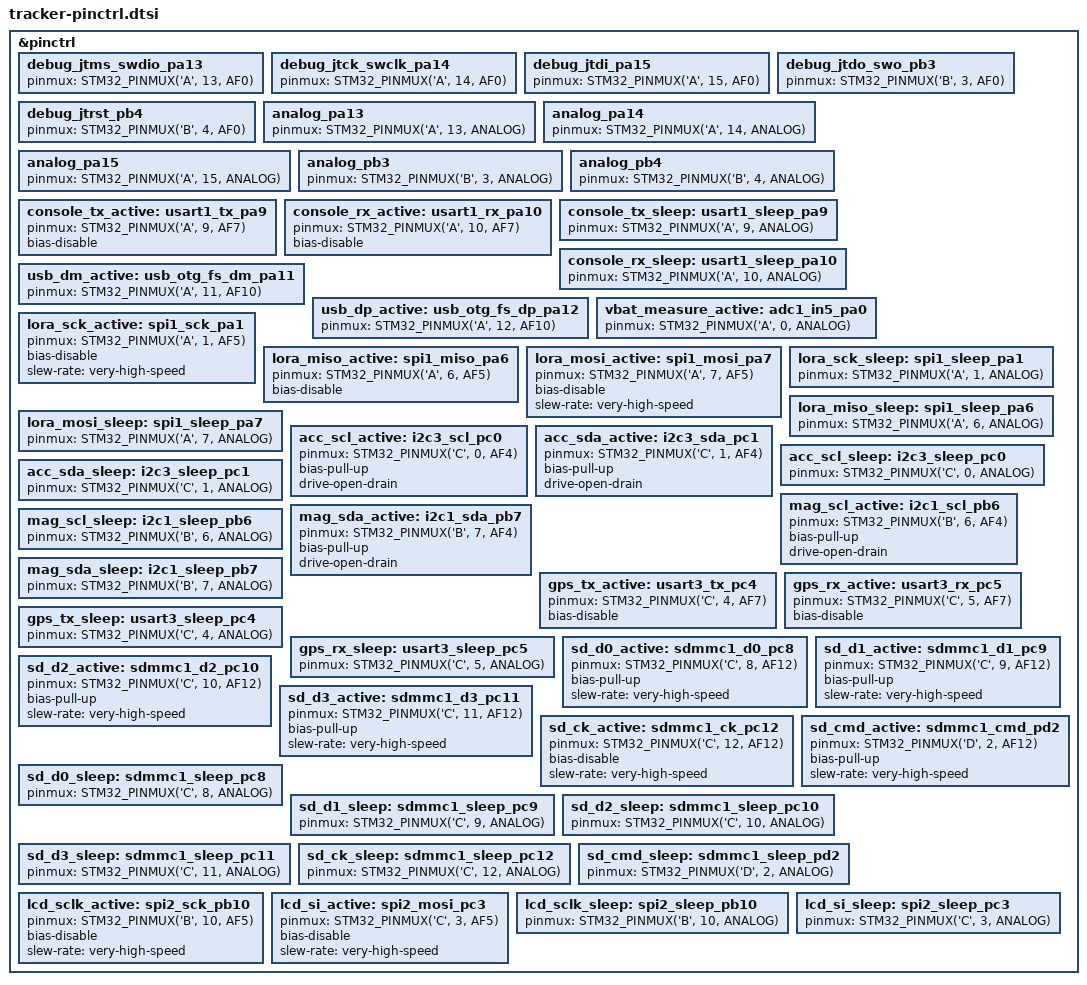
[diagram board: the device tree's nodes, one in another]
/*
 * Pin control definitions for the Tracker board
 * STM32U575RGT6 — LQFP-64
 *
 * Every peripheral has a "default" (active) and "sleep" (analog) state.
 * Pins are grouped by power domain so sleep can be applied per-domain.
 * Pin names reflect the connected component, not the STM32 peripheral.
 *
 * SPDX-License-Identifier: Apache-2.0
 */

#include <zephyr/dt-bindings/pinctrl/stm32-pinctrl.h>

&pinctrl {

	/* ==============================================================
	 * SWD / JTAG debug port (required by SoC dtsi swj_port node)
	 * ============================================================== */

	debug_jtms_swdio_pa13: debug_jtms_swdio_pa13 {
		pinmux = <STM32_PINMUX('A', 13, AF0)>;
	};
	debug_jtck_swclk_pa14: debug_jtck_swclk_pa14 {
		pinmux = <STM32_PINMUX('A', 14, AF0)>;
	};
	debug_jtdi_pa15: debug_jtdi_pa15 {
		pinmux = <STM32_PINMUX('A', 15, AF0)>;
	};
	debug_jtdo_swo_pb3: debug_jtdo_swo_pb3 {
		pinmux = <STM32_PINMUX('B', 3, AF0)>;
	};
	debug_jtrst_pb4: debug_jtrst_pb4 {
		pinmux = <STM32_PINMUX('B', 4, AF0)>;
	};
	analog_pa13: analog_pa13 {
		pinmux = <STM32_PINMUX('A', 13, ANALOG)>;
	};
	analog_pa14: analog_pa14 {
		pinmux = <STM32_PINMUX('A', 14, ANALOG)>;
	};
	analog_pa15: analog_pa15 {
		pinmux = <STM32_PINMUX('A', 15, ANALOG)>;
	};
	analog_pb3: analog_pb3 {
		pinmux = <STM32_PINMUX('B', 3, ANALOG)>;
	};
	analog_pb4: analog_pb4 {
		pinmux = <STM32_PINMUX('B', 4, ANALOG)>;
	};

	/* ==============================================================
	 * MCU Domain (always on)
	 * Console USART1, USB, ADC
	 * ============================================================== */

	/* Console UART (PA9 TX, PA10 RX) */
	console_tx_active: usart1_tx_pa9 {
		pinmux = <STM32_PINMUX('A', 9, AF7)>;
		bias-disable;
	};
	console_rx_active: usart1_rx_pa10 {
		pinmux = <STM32_PINMUX('A', 10, AF7)>;
		bias-disable;
	};
	console_tx_sleep: usart1_sleep_pa9 {
		pinmux = <STM32_PINMUX('A', 9, ANALOG)>;
	};
	console_rx_sleep: usart1_sleep_pa10 {
		pinmux = <STM32_PINMUX('A', 10, ANALOG)>;
	};

	/* USB OTG FS (PA11 D-, PA12 D+) */
	usb_dm_active: usb_otg_fs_dm_pa11 {
		pinmux = <STM32_PINMUX('A', 11, AF10)>;
	};
	usb_dp_active: usb_otg_fs_dp_pa12 {
		pinmux = <STM32_PINMUX('A', 12, AF10)>;
	};

	/* ADC1 — VBAT measurement (PA0 / IN5) */
	vbat_measure_active: adc1_in5_pa0 {
		pinmux = <STM32_PINMUX('A', 0, ANALOG)>;
	};

	/* ==============================================================
	 * 3V3 Domain (PB15 = 3V3_EN)
	 * LoRa SPI1, Accel I2C3, Mag I2C1, GPS USART3, SDMMC1
	 * ============================================================== */

	/* LoRa E22-900M22S via SPI1 (PA1 SCK, PA6 MISO, PA7 MOSI) */
	lora_sck_active: spi1_sck_pa1 {
		pinmux = <STM32_PINMUX('A', 1, AF5)>;
		bias-disable;
		slew-rate = "very-high-speed";
	};
	lora_miso_active: spi1_miso_pa6 {
		pinmux = <STM32_PINMUX('A', 6, AF5)>;
		bias-disable;
	};
	lora_mosi_active: spi1_mosi_pa7 {
		pinmux = <STM32_PINMUX('A', 7, AF5)>;
		bias-disable;
		slew-rate = "very-high-speed";
	};
	lora_sck_sleep: spi1_sleep_pa1 {
		pinmux = <STM32_PINMUX('A', 1, ANALOG)>;
	};
	lora_miso_sleep: spi1_sleep_pa6 {
		pinmux = <STM32_PINMUX('A', 6, ANALOG)>;
	};
	lora_mosi_sleep: spi1_sleep_pa7 {
		pinmux = <STM32_PINMUX('A', 7, ANALOG)>;
	};

	/* LSM6DSOTR Accelerometer via I2C3 (PC0 SCL, PC1 SDA) */
	acc_scl_active: i2c3_scl_pc0 {
		pinmux = <STM32_PINMUX('C', 0, AF4)>;
		bias-pull-up;
		drive-open-drain;
	};
	acc_sda_active: i2c3_sda_pc1 {
		pinmux = <STM32_PINMUX('C', 1, AF4)>;
		bias-pull-up;
		drive-open-drain;
	};
	acc_scl_sleep: i2c3_sleep_pc0 {
		pinmux = <STM32_PINMUX('C', 0, ANALOG)>;
	};
	acc_sda_sleep: i2c3_sleep_pc1 {
		pinmux = <STM32_PINMUX('C', 1, ANALOG)>;
	};

	/* LIS3MDLTR Magnetometer via I2C1 (PB6 SCL, PB7 SDA) */
	mag_scl_active: i2c1_scl_pb6 {
		pinmux = <STM32_PINMUX('B', 6, AF4)>;
		bias-pull-up;
		drive-open-drain;
	};
	mag_sda_active: i2c1_sda_pb7 {
		pinmux = <STM32_PINMUX('B', 7, AF4)>;
		bias-pull-up;
		drive-open-drain;
	};
	mag_scl_sleep: i2c1_sleep_pb6 {
		pinmux = <STM32_PINMUX('B', 6, ANALOG)>;
	};
	mag_sda_sleep: i2c1_sleep_pb7 {
		pinmux = <STM32_PINMUX('B', 7, ANALOG)>;
	};

	/* GPS MAX-M10S via USART3 (PC4 TX, PC5 RX) */
	gps_tx_active: usart3_tx_pc4 {
		pinmux = <STM32_PINMUX('C', 4, AF7)>;
		bias-disable;
	};
	gps_rx_active: usart3_rx_pc5 {
		pinmux = <STM32_PINMUX('C', 5, AF7)>;
		bias-disable;
	};
	gps_tx_sleep: usart3_sleep_pc4 {
		pinmux = <STM32_PINMUX('C', 4, ANALOG)>;
	};
	gps_rx_sleep: usart3_sleep_pc5 {
		pinmux = <STM32_PINMUX('C', 5, ANALOG)>;
	};

	/* SD Card via SDMMC1 (4-bit wide bus) */
	sd_d0_active: sdmmc1_d0_pc8 {
		pinmux = <STM32_PINMUX('C', 8, AF12)>;
		bias-pull-up;
		slew-rate = "very-high-speed";
	};
	sd_d1_active: sdmmc1_d1_pc9 {
		pinmux = <STM32_PINMUX('C', 9, AF12)>;
		bias-pull-up;
		slew-rate = "very-high-speed";
	};
	sd_d2_active: sdmmc1_d2_pc10 {
		pinmux = <STM32_PINMUX('C', 10, AF12)>;
		bias-pull-up;
		slew-rate = "very-high-speed";
	};
	sd_d3_active: sdmmc1_d3_pc11 {
		pinmux = <STM32_PINMUX('C', 11, AF12)>;
		bias-pull-up;
		slew-rate = "very-high-speed";
	};
	sd_ck_active: sdmmc1_ck_pc12 {
		pinmux = <STM32_PINMUX('C', 12, AF12)>;
		bias-disable;
		slew-rate = "very-high-speed";
	};
	sd_cmd_active: sdmmc1_cmd_pd2 {
		pinmux = <STM32_PINMUX('D', 2, AF12)>;
		bias-pull-up;
		slew-rate = "very-high-speed";
	};
	sd_d0_sleep: sdmmc1_sleep_pc8 {
		pinmux = <STM32_PINMUX('C', 8, ANALOG)>;
	};
	sd_d1_sleep: sdmmc1_sleep_pc9 {
		pinmux = <STM32_PINMUX('C', 9, ANALOG)>;
	};
	sd_d2_sleep: sdmmc1_sleep_pc10 {
		pinmux = <STM32_PINMUX('C', 10, ANALOG)>;
	};
	sd_d3_sleep: sdmmc1_sleep_pc11 {
		pinmux = <STM32_PINMUX('C', 11, ANALOG)>;
	};
	sd_ck_sleep: sdmmc1_sleep_pc12 {
		pinmux = <STM32_PINMUX('C', 12, ANALOG)>;
	};
	sd_cmd_sleep: sdmmc1_sleep_pd2 {
		pinmux = <STM32_PINMUX('D', 2, ANALOG)>;
	};

	/* ==============================================================
	 * 5V Domain (PA8 = 5V_EN)
	 * Sharp LS027B7DH01A LCD via SPI2
	 * ============================================================== */

	/* Sharp LCD (PB10 SCLK, PC3 SI/MOSI, write-only) */
	lcd_sclk_active: spi2_sck_pb10 {
		pinmux = <STM32_PINMUX('B', 10, AF5)>;
		bias-disable;
		slew-rate = "very-high-speed";
	};
	lcd_si_active: spi2_mosi_pc3 {
		pinmux = <STM32_PINMUX('C', 3, AF5)>;
		bias-disable;
		slew-rate = "very-high-speed";
	};
	lcd_sclk_sleep: spi2_sleep_pb10 {
		pinmux = <STM32_PINMUX('B', 10, ANALOG)>;
	};
	lcd_si_sleep: spi2_sleep_pc3 {
		pinmux = <STM32_PINMUX('C', 3, ANALOG)>;
	};
};
